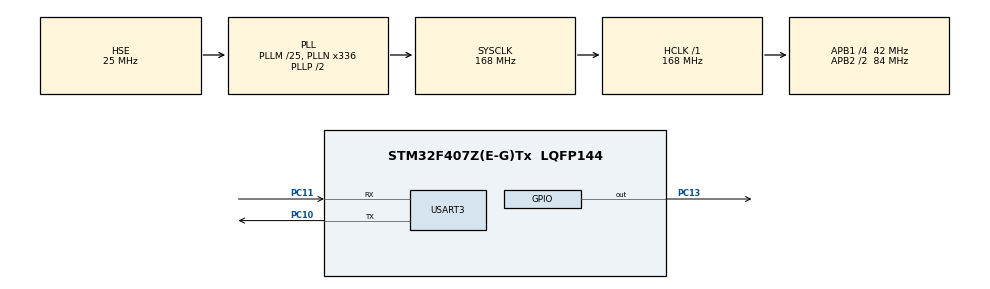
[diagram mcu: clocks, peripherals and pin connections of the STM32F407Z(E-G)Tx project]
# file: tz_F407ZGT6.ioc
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Dma.Request0=USART3_TX
Dma.Request1=USART3_RX
Dma.USART3_RX.1.Direction=DMA_PERIPH_TO_MEMORY
Dma.USART3_RX.1.FIFOMode=DMA_FIFOMODE_DISABLE
Dma.USART3_RX.1.Instance=DMA1_Stream1
Dma.USART3_RX.1.MemDataAlignment=DMA_MDATAALIGN_BYTE
Dma.USART3_RX.1.MemInc=DMA_MINC_ENABLE
Dma.USART3_RX.1.Mode=DMA_NORMAL
Dma.USART3_RX.1.PeriphDataAlignment=DMA_PDATAALIGN_BYTE
Dma.USART3_RX.1.PeriphInc=DMA_PINC_DISABLE
Dma.USART3_RX.1.Priority=DMA_PRIORITY_LOW
Dma.USART3_TX.0.Direction=DMA_MEMORY_TO_PERIPH
Dma.USART3_TX.0.FIFOMode=DMA_FIFOMODE_DISABLE
Dma.USART3_TX.0.Instance=DMA1_Stream3
Dma.USART3_TX.0.MemDataAlignment=DMA_MDATAALIGN_BYTE
Dma.USART3_TX.0.MemInc=DMA_MINC_ENABLE
Dma.USART3_TX.0.Mode=DMA_NORMAL
Dma.USART3_TX.0.PeriphDataAlignment=DMA_PDATAALIGN_BYTE
Dma.USART3_TX.0.PeriphInc=DMA_PINC_DISABLE
Dma.USART3_TX.0.Priority=DMA_PRIORITY_LOW
FREERTOS.Tasks01=defaultTask,24,128,StartDefaultTask,Default,NULL,Dynamic,NULL,NULL
Mcu.Family=STM32F4
Mcu.Name=STM32F407Z(E-G)Tx
Mcu.Package=LQFP144
NVIC.DMA1_Stream1_IRQn=true\:5\:0\:false\:false\:true\:true\:false\:true
NVIC.DMA1_Stream3_IRQn=true\:5\:0\:false\:false\:true\:true\:false\:true
NVIC.PriorityGroup=NVIC_PRIORITYGROUP_4
NVIC.TIM2_IRQn=true\:0\:0\:false\:false\:true\:false\:false\:true
NVIC.TimeBase=TIM2_IRQn
NVIC.TimeBaseIP=TIM2
NVIC.USART3_IRQn=true\:5\:0\:false\:false\:true\:true\:true\:true
PA13.Mode=Serial_Wire
PA13.Signal=SYS_JTMS-SWDIO
PA14.Mode=Serial_Wire
PA14.Signal=SYS_JTCK-SWCLK
PC10.Mode=Asynchronous
PC10.Signal=USART3_TX
PC11.Mode=Asynchronous
PC11.Signal=USART3_RX
PC13-ANTI_TAMP.Signal=GPIO_Output
PH0-OSC_IN.Mode=HSE-External-Oscillator
PH0-OSC_IN.Signal=RCC_OSC_IN
PH1-OSC_OUT.Mode=HSE-External-Oscillator
PH1-OSC_OUT.Signal=RCC_OSC_OUT
ProjectManager.HeapSize=0x200
ProjectManager.StackSize=0x400
ProjectManager.TargetToolchain=STM32CubeIDE
RCC.48MHZClocksFreq_Value=84000000
RCC.AHBFreq_Value=168000000
RCC.APB1CLKDivider=RCC_HCLK_DIV4
RCC.APB1Freq_Value=42000000
RCC.APB1TimFreq_Value=84000000
RCC.APB2CLKDivider=RCC_HCLK_DIV2
RCC.APB2Freq_Value=84000000
RCC.APB2TimFreq_Value=168000000
RCC.CortexFreq_Value=168000000
RCC.HCLKFreq_Value=168000000
RCC.HSE_VALUE=25000000
RCC.HSI_VALUE=16000000
RCC.PLLM=25
RCC.PLLN=336
RCC.PLLSourceVirtual=RCC_PLLSOURCE_HSE
RCC.SYSCLKFreq_VALUE=168000000
RCC.SYSCLKSource=RCC_SYSCLKSOURCE_PLLCLK
RCC.VCOOutputFreq_Value=336000000
USART3.VirtualMode=VM_ASYNC
VP_FREERTOS_VS_CMSIS_V2.Mode=CMSIS_V2
VP_SYS_VS_tim2.Mode=TIM2
board=custom

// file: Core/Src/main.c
/* USER CODE BEGIN Header */
/**
  ******************************************************************************
  * @file           : main.c
  * @brief          : Main program body
  ******************************************************************************
  * @attention
  *
  * <h2><center>&copy; Copyright (c) 2024 STMicroelectronics.
  * All rights reserved.</center></h2>
  *
  * This software component is licensed by ST under BSD 3-Clause license,
  * the "License"; You may not use this file except in compliance with the
  * License. You may obtain a copy of the License at:
  *                        opensource.org/licenses/BSD-3-Clause
  *
  ******************************************************************************
  */
/* USER CODE END Header */
#include "main.h"
#include "cmsis_os.h"
#include "dma.h"
#include "usart.h"
#include "gpio.h"

void SystemClock_Config(void);
void MX_FREERTOS_Init(void);

int main(void)
{

  /* MCU Configuration--------------------------------------------------------*/

  /* Reset of all peripherals, Initializes the Flash interface and the Systick. */
  HAL_Init();

  /* Configure the system clock */
  SystemClock_Config();

  /* Initialize all configured peripherals */
  MX_GPIO_Init();
  MX_DMA_Init();
  MX_USART3_UART_Init();

  /* Init scheduler */
  osKernelInitialize();  /* Call init function for freertos objects (in freertos.c) */
  MX_FREERTOS_Init();
  /* Start scheduler */
  osKernelStart();

  /* We should never get here as control is now taken by the scheduler */
  /* Infinite loop */
  while (1)
  {

  }
}

void SystemClock_Config(void)
{
  RCC_OscInitTypeDef RCC_OscInitStruct = {0};
  RCC_ClkInitTypeDef RCC_ClkInitStruct = {0};

  /** Configure the main internal regulator output voltage
  */
  __HAL_RCC_PWR_CLK_ENABLE();
  __HAL_PWR_VOLTAGESCALING_CONFIG(PWR_REGULATOR_VOLTAGE_SCALE1);
  /** Initializes the RCC Oscillators according to the specified parameters
  * in the RCC_OscInitTypeDef structure.
  */
  RCC_OscInitStruct.OscillatorType = RCC_OSCILLATORTYPE_HSE;
  RCC_OscInitStruct.HSEState = RCC_HSE_ON;
  RCC_OscInitStruct.PLL.PLLState = RCC_PLL_ON;
  RCC_OscInitStruct.PLL.PLLSource = RCC_PLLSOURCE_HSE;
  RCC_OscInitStruct.PLL.PLLM = 25;
  RCC_OscInitStruct.PLL.PLLN = 336;
  RCC_OscInitStruct.PLL.PLLP = RCC_PLLP_DIV2;
  RCC_OscInitStruct.PLL.PLLQ = 4;
  if (HAL_RCC_OscConfig(&RCC_OscInitStruct) != HAL_OK)
  {
    Error_Handler();
  }
  /** Initializes the CPU, AHB and APB buses clocks
  */
  RCC_ClkInitStruct.ClockType = RCC_CLOCKTYPE_HCLK|RCC_CLOCKTYPE_SYSCLK
                              |RCC_CLOCKTYPE_PCLK1|RCC_CLOCKTYPE_PCLK2;
  RCC_ClkInitStruct.SYSCLKSource = RCC_SYSCLKSOURCE_PLLCLK;
  RCC_ClkInitStruct.AHBCLKDivider = RCC_SYSCLK_DIV1;
  RCC_ClkInitStruct.APB1CLKDivider = RCC_HCLK_DIV4;
  RCC_ClkInitStruct.APB2CLKDivider = RCC_HCLK_DIV2;

  if (HAL_RCC_ClockConfig(&RCC_ClkInitStruct, FLASH_LATENCY_5) != HAL_OK)
  {
    Error_Handler();
  }
}

 /**
  * @brief  Period elapsed callback in non blocking mode
  * @note   This function is called  when TIM2 interrupt took place, inside
  * HAL_TIM_IRQHandler(). It makes a direct call to HAL_IncTick() to increment
  * a global variable "uwTick" used as application time base.
  * @param  htim : TIM handle
  * @retval None
  */
void HAL_TIM_PeriodElapsedCallback(TIM_HandleTypeDef *htim)
{
  if (htim->Instance == TIM2) {
    HAL_IncTick();
  }
}

void Error_Handler(void)
{
  __disable_irq();
  while (1)
  {
  }
}

/************************ (C) COPYRIGHT STMicroelectronics *****END OF FILE****/

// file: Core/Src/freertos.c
/* USER CODE BEGIN Header */
/**
  ******************************************************************************
  * File Name          : freertos.c
  * Description        : Code for freertos applications
  ******************************************************************************
  * @attention
  *
  * <h2><center>&copy; Copyright (c) 2024 STMicroelectronics.
  * All rights reserved.</center></h2>
  *
  * This software component is licensed by ST under Ultimate Liberty license
  * SLA0044, the "License"; You may not use this file except in compliance with
  * the License. You may obtain a copy of the License at:
  *                             www.st.com/SLA0044
  *
  ******************************************************************************
  */
/* USER CODE END Header */

#include "FreeRTOS.h"
#include "task.h"
#include "main.h"
#include "cmsis_os.h"

/* USER CODE BEGIN Includes */
#include "usart.h"
/* USER CODE END Includes */

/* USER CODE BEGIN Variables */

osThreadId_t blinkPC13TaskHandle;
const osThreadAttr_t blinkPC13Task_attributes = {
  .name = "blinkPC13Task",
  .priority = (osPriority_t) osPriorityNormal,
  .stack_size = 128 * 4
};

osThreadId_t sendMsgTaskHandle;
const osThreadAttr_t sendMsgTask_attributes = {
  .name = "sendMsgTask",
  .priority = (osPriority_t) osPriorityNormal,
  .stack_size = 128 * 4
};

uint8_t pDataRxBuffer[1000] = {0};
uint8_t pDataTxBuffer[] = "hello world";
uint8_t TxBegin = 1;

/* USER CODE END Variables */
/* Definitions for defaultTask */
osThreadId_t defaultTaskHandle;
const osThreadAttr_t defaultTask_attributes = {
  .name = "defaultTask",
  .priority = (osPriority_t) osPriorityNormal,
  .stack_size = 128 * 4
};

/* USER CODE BEGIN FunctionPrototypes */

void StartBlinkPC13Task(void *argument);

void StartSendMsgTask(void *argument);
/* USER CODE END FunctionPrototypes */

void StartDefaultTask(void *argument);

void MX_FREERTOS_Init(void); /* (MISRA C 2004 rule 8.1) */

void MX_FREERTOS_Init(void) {
  /* USER CODE BEGIN Init */
  HAL_UART_Receive_DMA(&huart3, pDataRxBuffer, sizeof(pDataRxBuffer));
  /* USER CODE END Init */

  /* Create the thread(s) */
  /* creation of defaultTask */
  defaultTaskHandle = osThreadNew(StartDefaultTask, NULL, &defaultTask_attributes);

  /* USER CODE BEGIN RTOS_THREADS */
  blinkPC13TaskHandle = osThreadNew(StartBlinkPC13Task, NULL, &blinkPC13Task_attributes);
  /* add threads, ... */
  sendMsgTaskHandle = osThreadNew(StartSendMsgTask, NULL, &sendMsgTask_attributes);
  /* USER CODE END RTOS_THREADS */

}

/* USER CODE BEGIN Header_StartDefaultTask */
/**
  * @brief  Function implementing the defaultTask thread.
  * @param  argument: Not used
  * @retval None
  */
void StartBlinkPC13Task(void *argument)
{
	for(;;)
	{
		HAL_GPIO_TogglePin(GPIOC, GPIO_PIN_13);
		osDelay (1000);
	}

}
void StartSendMsgTask(void *argument)
{
	for(;;)
	{
		osDelay (2000);
		if(TxBegin){
			HAL_UART_Transmit_DMA(&huart3, pDataTxBuffer, sizeof(pDataTxBuffer));
		}
	}

}
/* USER CODE END Header_StartDefaultTask */
void StartDefaultTask(void *argument)
{
  for(;;)
  {
    osDelay(1);
  }
}

/************************ (C) COPYRIGHT STMicroelectronics *****END OF FILE****/
